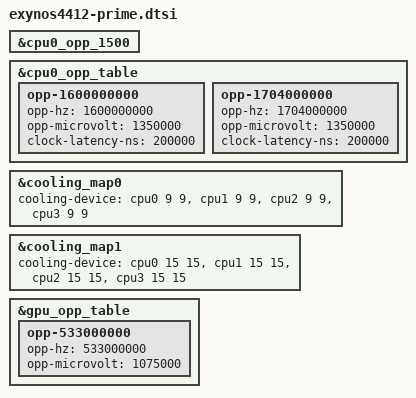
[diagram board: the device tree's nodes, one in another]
&cpu0_opp_1500 {
	/delete-property/turbo-mode;
};
&cpu0_opp_table {
	opp-1600000000 {
		opp-hz = /bits/ 64 <1600000000>;
		opp-microvolt = <1350000>;
		clock-latency-ns = <200000>;
	};
	opp-1704000000 {
		opp-hz = /bits/ 64 <1704000000>;
		opp-microvolt = <1350000>;
		clock-latency-ns = <200000>;
	};
};
&cooling_map0 {
	cooling-device = <&cpu0 9 9>, <&cpu1 9 9>,
			 <&cpu2 9 9>, <&cpu3 9 9>;
};
&cooling_map1 {
	cooling-device = <&cpu0 15 15>, <&cpu1 15 15>,
			 <&cpu2 15 15>, <&cpu3 15 15>;
};
&gpu_opp_table {
	opp-533000000 {
		opp-hz = /bits/ 64 <533000000>;
		opp-microvolt = <1075000>;
	};
};
